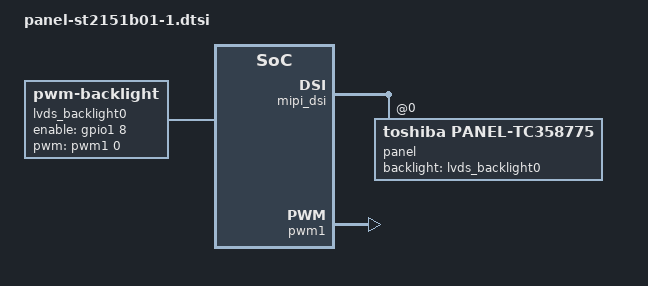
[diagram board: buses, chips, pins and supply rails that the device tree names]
/*
 * Copyright 2019 MYiR Devices
 */
/{
	lvds_backlight0: lvds_backlight@0 {
		compatible = "pwm-backlight";
		pwms = <&pwm1 0 5000000 >;
		pinctrl-0 = <&pinctrl_lvds0_pwm1>;
		enable-gpios = <&gpio1 8 GPIO_ACTIVE_HIGH>; 
		brightness-levels = < 0  1  2  3  4  5  6  7  8  9
				     10 11 12 13 14 15 16 17 18 19
				     20 21 22 23 24 25 26 27 28 29
				     30 31 32 33 34 35 36 37 38 39
				     40 41 42 43 44 45 46 47 48 49
				     50 51 52 53 54 55 56 57 58 59
				     60 61 62 63 64 65 66 67 68 69
				     70 71 72 73 74 75 76 77 78 79
				     80 81 82 83 84 85 86 87 88 89
				     90 91 92 93 94 95 96 97 98 99
				    100>;
		default-brightness-level = <80>;
	};
};

&lcdif{
	max-res = <1920>, <1080>;
};

&mipi_dsi{
	panel@0 {
		compatible = "toshiba,panel-tc358775";
		reg = <0>;

		panel-width-mm = <1920>;
		panel-height-mm = <1080>;
		
		toshiba,debug = <1>;
		toshiba,ppi_tx_rx_ta = <0x000A000C>;
		toshiba,ppi_lptxtimecnt = <0x00000008>;
		toshiba,ppi_d0s_clrsipocount = <0x0000000D>;
		toshiba,ppi_d1s_clrsipocount = <0x0000000D>;
		toshiba,ppi_d2s_clrsipocount = <0x0000000D>;
		toshiba,ppi_d3s_clrsipocount = <0x0000000D>;
		toshiba,ppi_laneenable = <0x0000001f>; 
		toshiba,dsi_laneenable = <0x0000001f>; 
		toshiba,ppi_sartppi = <0x00000001>; 
		toshiba,dsi_sartppi = <0x00000001>;
		
		toshiba,vpctrl = <0x03F00100>; 
		toshiba,htim1 = <0x00550006>;
		toshiba,htim2 = <0x00780780>;
		toshiba,vtim1 = <0x00280008>;
		toshiba,vtim2 = <0x005a0438>;
		toshiba,vfuen = <0x00000001>;
		toshiba,lvphy0 = <0x00448006>;
		toshiba,lvphy0_1 = <0x00048006>;
		toshiba,sysrst = <0x00000004>; 

		toshiba,lvmx0003 = <0x03020100>;
		toshiba,lvmx0407 = <0x08050704>;
		toshiba,lvmx0811 = <0x0f0e0a09>;
		toshiba,lvmx1215 = <0x100d0c0b>;
		toshiba,lvmx1619 = <0x12111716>;
		toshiba,lvmx2023 = <0x1b151413>;
		toshiba,lvmx2427 = <0x061a1918>;
		toshiba,lvcfg = <0x00000433>;
		
		backlight = <&lvds_backlight0>;
		client-device  = <&tc358775>;
		
		display-timings {
				native-mode = <&timing0>;
				timing0:timing0{
					clock-frequency = <148500000>;
					hactive = <1920>;
					hsync-len = <6>;
					hback-porch = <85>;
					hfront-porch = <120>;
					vactive = <1079>;
					vsync-len = <8>;
					vback-porch = <41>;
					vfront-porch = <80>;
					
					vsync-active = <0>;
					hsync-active =<0>;
					de-active =<0>;
					pixelclk-active =<0>;
				};
		};
		
	};

};

&iomuxc {
	imx8mm-evk {
		pinctrl_lvds0_pwm1: lvds0pwm1grp {
			fsl,pins = <
				MX8MM_IOMUXC_GPIO1_IO08_GPIO1_IO8	0x19
				
			>;
		};
		pinctrl_pwm1: lvds0pwm1grp {
			fsl,pins = <
				MX8MM_IOMUXC_GPIO1_IO01_PWM1_OUT 0x19
			>;
		};


	};

};

&pwm1 {
	pinctrl-names = "default";
	pinctrl-0 = <&pinctrl_pwm1>;
	status = "okay";
};
